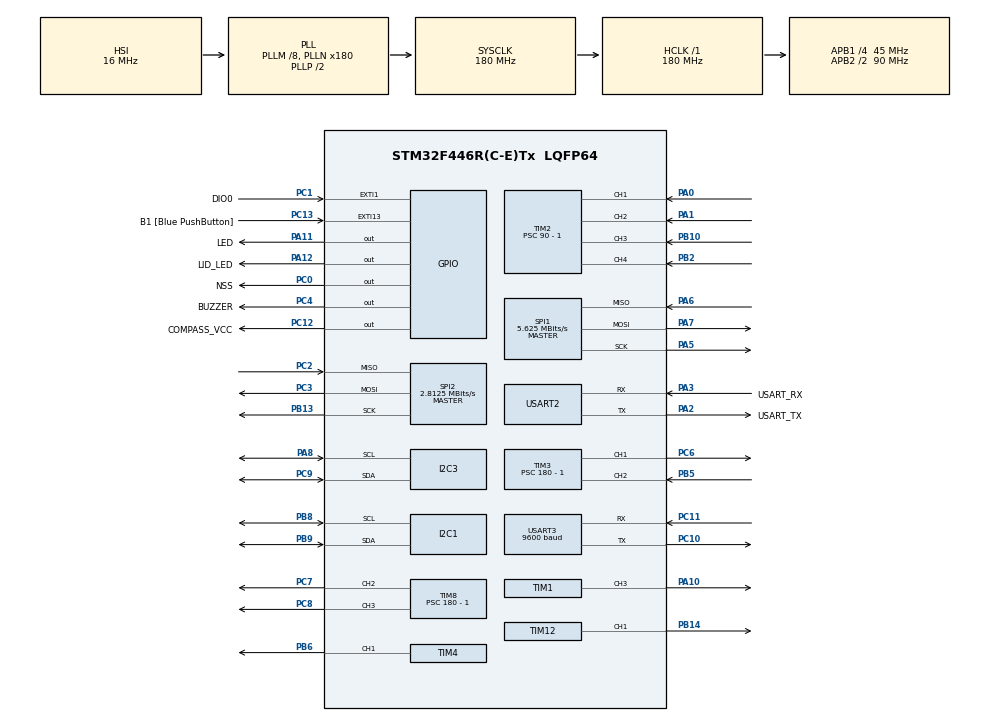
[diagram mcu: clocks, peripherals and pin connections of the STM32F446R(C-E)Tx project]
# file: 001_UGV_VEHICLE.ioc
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FREERTOS.Tasks01=defaultTask,24,128,StartDefaultTask,Default,NULL,Dynamic,NULL,NULL
FREERTOS.configUSE_NEWLIB_REENTRANT=1
IWDG.Prescaler=IWDG_PRESCALER_8
IWDG.Reload=2000
Mcu.Family=STM32F4
Mcu.Name=STM32F446R(C-E)Tx
Mcu.Package=LQFP64
NVIC.EXTI1_IRQn=true\:5\:0\:false\:false\:true\:true\:true\:true\:true
NVIC.PriorityGroup=NVIC_PRIORITYGROUP_4
NVIC.TIM2_IRQn=true\:5\:0\:false\:false\:true\:true\:true\:true\:true
NVIC.TIM6_DAC_IRQn=true\:15\:0\:false\:false\:true\:false\:false\:true\:true
NVIC.TimeBase=TIM6_DAC_IRQn
NVIC.TimeBaseIP=TIM6
NVIC.USART3_IRQn=true\:5\:0\:false\:false\:true\:true\:true\:true\:true
PA0-WKUP.Signal=S_TIM2_CH1_ETR
PA1.Signal=S_TIM2_CH2
PA10.Signal=S_TIM1_CH3
PA11.GPIO_Label=LED
PA11.Signal=GPIO_Output
PA12.GPIO_Label=LID_LED
PA12.Signal=GPIO_Output
PA13.GPIO_Label=TMS
PA13.Mode=Serial_Wire
PA13.Signal=SYS_JTMS-SWDIO
PA14.GPIO_Label=TCK
PA14.Mode=Serial_Wire
PA14.Signal=SYS_JTCK-SWCLK
PA2.GPIO_Label=USART_TX
PA2.Mode=Asynchronous
PA2.Signal=USART2_TX
PA3.GPIO_Label=USART_RX
PA3.Mode=Asynchronous
PA3.Signal=USART2_RX
PA5.Mode=Full_Duplex_Master
PA5.Signal=SPI1_SCK
PA6.Mode=Full_Duplex_Master
PA6.Signal=SPI1_MISO
PA7.Mode=Full_Duplex_Master
PA7.Signal=SPI1_MOSI
PA8.Mode=I2C
PA8.Signal=I2C3_SCL
PB10.Signal=S_TIM2_CH3
PB13.Mode=Full_Duplex_Master
PB13.Signal=SPI2_SCK
PB14.Signal=S_TIM12_CH1
PB2.Signal=S_TIM2_CH4
PB3.GPIO_Label=SWO
PB3.Signal=SYS_JTDO-SWO
PB5.Signal=S_TIM3_CH2
PB6.Signal=S_TIM4_CH1
PB8.Mode=I2C
PB8.Signal=I2C1_SCL
PB9.Mode=I2C
PB9.Signal=I2C1_SDA
PC0.GPIO_Label=NSS
PC0.PinState=GPIO_PIN_SET
PC0.Signal=GPIO_Output
PC1.GPIO_Label=DIO0
PC1.Signal=GPXTI1
PC10.Mode=Asynchronous
PC10.Signal=USART3_TX
PC11.Mode=Asynchronous
PC11.Signal=USART3_RX
PC12.GPIO_Label=COMPASS_VCC
PC12.Signal=GPIO_Output
PC13.GPIO_Label=B1 [Blue PushButton]
PC13.GPIO_ModeDefaultEXTI=GPIO_MODE_IT_FALLING
PC13.Signal=GPXTI13
PC2.Mode=Full_Duplex_Master
PC2.Signal=SPI2_MISO
PC3.Mode=Full_Duplex_Master
PC3.Signal=SPI2_MOSI
PC4.GPIO_Label=BUZZER
PC4.Signal=GPIO_Output
PC6.Signal=S_TIM3_CH1
PC7.Signal=S_TIM8_CH2
PC8.Signal=S_TIM8_CH3
PC9.Mode=I2C
PC9.Signal=I2C3_SDA
PH0-OSC_IN.Mode=HSE-External-Oscillator
PH0-OSC_IN.Signal=RCC_OSC_IN
PH1-OSC_OUT.Mode=HSE-External-Oscillator
PH1-OSC_OUT.Signal=RCC_OSC_OUT
ProjectManager.HeapSize=0x200
ProjectManager.StackSize=0x400
ProjectManager.TargetToolchain=STM32CubeIDE
RCC.48MHZClocksFreq_Value=84000000
RCC.AHBFreq_Value=180000000
RCC.APB1CLKDivider=RCC_HCLK_DIV4
RCC.APB1Freq_Value=45000000
RCC.APB1TimFreq_Value=90000000
RCC.APB2CLKDivider=RCC_HCLK_DIV2
RCC.APB2Freq_Value=90000000
RCC.APB2TimFreq_Value=180000000
RCC.CortexFreq_Value=180000000
RCC.FLatency-AdvancedSettings=FLASH_LATENCY_5
RCC.HCLKFreq_Value=180000000
RCC.HSE_VALUE=8000000
RCC.HSI_VALUE=16000000
RCC.PLLM=8
RCC.PLLN=180
RCC.SYSCLKFreq_VALUE=180000000
RCC.SYSCLKSource=RCC_SYSCLKSOURCE_PLLCLK
RCC.USBFreq_Value=180000000
RCC.VCOOutputFreq_Value=360000000
SH.S_TIM12_CH1.0=TIM12_CH1,PWM Generation1 CH1
SH.S_TIM1_CH3.0=TIM1_CH3,PWM Generation3 CH3
SH.S_TIM2_CH1_ETR.0=TIM2_CH1,Input_Capture1_from_TI1
SH.S_TIM2_CH2.0=TIM2_CH2,Input_Capture2_from_TI2
SH.S_TIM2_CH3.0=TIM2_CH3,Input_Capture3_from_TI3
SH.S_TIM2_CH4.0=TIM2_CH4,Input_Capture4_from_TI4
SH.S_TIM3_CH1.0=TIM3_CH1,PWM Generation1 CH1
SH.S_TIM3_CH2.0=TIM3_CH2,Input_Capture2_from_TI2
SH.S_TIM4_CH1.0=TIM4_CH1,PWM Generation1 CH1
SH.S_TIM8_CH2.0=TIM8_CH2,PWM Generation2 CH2
SH.S_TIM8_CH3.0=TIM8_CH3,PWM Generation3 CH3
SPI1.BaudRatePrescaler=SPI_BAUDRATEPRESCALER_16
SPI1.CalculateBaudRate=5.625 MBits/s
SPI1.Direction=SPI_DIRECTION_2LINES
SPI1.Mode=SPI_MODE_MASTER
SPI1.VirtualType=VM_MASTER
SPI2.BaudRatePrescaler=SPI_BAUDRATEPRESCALER_16
SPI2.CalculateBaudRate=2.8125 MBits/s
SPI2.Direction=SPI_DIRECTION_2LINES
SPI2.Mode=SPI_MODE_MASTER
SPI2.VirtualType=VM_MASTER
TIM1.Channel-PWM\ Generation3\ CH3=TIM_CHANNEL_3
TIM1.Period=100
TIM1.Prescaler=180  - 1
TIM12.Channel-PWM\ Generation1\ CH1=TIM_CHANNEL_1
TIM12.Period=1000-1
TIM12.Prescaler=1800-1
TIM2.Channel-Input_Capture1_from_TI1=TIM_CHANNEL_1
TIM2.Channel-Input_Capture2_from_TI2=TIM_CHANNEL_2
TIM2.Channel-Input_Capture3_from_TI3=TIM_CHANNEL_3
TIM2.Channel-Input_Capture4_from_TI4=TIM_CHANNEL_4
TIM2.ICPolarity_CH1=TIM_INPUTCHANNELPOLARITY_BOTHEDGE
TIM2.ICPolarity_CH2=TIM_INPUTCHANNELPOLARITY_BOTHEDGE
TIM2.ICPolarity_CH3=TIM_INPUTCHANNELPOLARITY_BOTHEDGE
TIM2.ICPolarity_CH4=TIM_INPUTCHANNELPOLARITY_BOTHEDGE
TIM2.Prescaler=90 - 1
TIM3.Channel-Input_Capture2_from_TI2=TIM_CHANNEL_2
TIM3.Channel-PWM\ Generation1\ CH1=TIM_CHANNEL_1
TIM3.Period=100
TIM3.Prescaler=180 - 1
TIM4.Channel-PWM\ Generation1\ CH1=TIM_CHANNEL_1
TIM4.Period=100
TIM4.Prescaler=180 - 1
TIM8.Channel-PWM\ Generation2\ CH2=TIM_CHANNEL_2
TIM8.Channel-PWM\ Generation3\ CH3=TIM_CHANNEL_3
TIM8.OCMode_PWM-PWM\ Generation3\ CH3=TIM_OCMODE_PWM1
TIM8.Period=100
TIM8.Prescaler=180 - 1
USART2.VirtualMode=VM_ASYNC
USART3.BaudRate=9600
USART3.VirtualMode=VM_ASYNC
VP_FREERTOS_VS_CMSIS_V2.Mode=CMSIS_V2
VP_IWDG_VS_IWDG.Mode=IWDG_Activate
VP_SYS_VS_tim6.Mode=TIM6
board=NUCLEO-F446RE

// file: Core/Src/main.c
/* USER CODE BEGIN Header */
/**
  ******************************************************************************
  * @file           : main.c
  * @brief          : Main program body
  ******************************************************************************
  * @attention
  *
  * Copyright (c) 2024 STMicroelectronics.
  * All rights reserved.
  *
  * This software is licensed under terms that can be found in the LICENSE file
  * in the root directory of this software component.
  * If no LICENSE file comes with this software, it is provided AS-IS.
  *
  ******************************************************************************
  */
/* USER CODE END Header */
#include "main.h"
#include "cmsis_os.h"
#include "i2c.h"
#include "iwdg.h"
#include "spi.h"
#include "tim.h"
#include "usart.h"
#include "gpio.h"

/* USER CODE BEGIN Includes */

#include "ugvMain.h"

/* USER CODE END Includes */

void SystemClock_Config(void);
void MX_FREERTOS_Init(void);

int main(void)
{

  /* MCU Configuration--------------------------------------------------------*/

  /* Reset of all peripherals, Initializes the Flash interface and the Systick. */
  HAL_Init();

  /* Configure the system clock */
  SystemClock_Config();

  /* Initialize all configured peripherals */
  MX_GPIO_Init();
  MX_USART2_UART_Init();
  MX_TIM2_Init();
  MX_SPI1_Init();
  MX_TIM12_Init();
  MX_I2C1_Init();
  MX_TIM3_Init();
  MX_TIM4_Init();
  MX_SPI2_Init();
  MX_USART3_UART_Init();
  MX_IWDG_Init();
  MX_TIM8_Init();
  MX_TIM1_Init();
  MX_I2C3_Init();

//  /* Init scheduler */
//  osKernelInitialize();
//
//  /* Call init function for freertos objects (in freertos.c) */
//  MX_FREERTOS_Init();
//
//  /* Start scheduler */
//  osKernelStart();
//
//  /* We should never get here as control is now taken by the scheduler */
//  /* Infinite loop */
//  /* USER CODE BEGIN WHILE */

  while (1)
  {
    /* USER CODE END WHILE */

    /* USER CODE BEGIN 3 */

	  ugvMain();
	  break;

  }
  /* USER CODE END 3 */
}

void SystemClock_Config(void)
{
  RCC_OscInitTypeDef RCC_OscInitStruct = {0};
  RCC_ClkInitTypeDef RCC_ClkInitStruct = {0};

  /** Configure the main internal regulator output voltage
  */
  __HAL_RCC_PWR_CLK_ENABLE();
  __HAL_PWR_VOLTAGESCALING_CONFIG(PWR_REGULATOR_VOLTAGE_SCALE1);

  /** Initializes the RCC Oscillators according to the specified parameters
  * in the RCC_OscInitTypeDef structure.
  */
  RCC_OscInitStruct.OscillatorType = RCC_OSCILLATORTYPE_HSI|RCC_OSCILLATORTYPE_LSI;
  RCC_OscInitStruct.HSIState = RCC_HSI_ON;
  RCC_OscInitStruct.HSICalibrationValue = RCC_HSICALIBRATION_DEFAULT;
  RCC_OscInitStruct.LSIState = RCC_LSI_ON;
  RCC_OscInitStruct.PLL.PLLState = RCC_PLL_ON;
  RCC_OscInitStruct.PLL.PLLSource = RCC_PLLSOURCE_HSI;
  RCC_OscInitStruct.PLL.PLLM = 8;
  RCC_OscInitStruct.PLL.PLLN = 180;
  RCC_OscInitStruct.PLL.PLLP = RCC_PLLP_DIV2;
  RCC_OscInitStruct.PLL.PLLQ = 2;
  RCC_OscInitStruct.PLL.PLLR = 2;
  if (HAL_RCC_OscConfig(&RCC_OscInitStruct) != HAL_OK)
  {
    Error_Handler();
  }

  /** Activate the Over-Drive mode
  */
  if (HAL_PWREx_EnableOverDrive() != HAL_OK)
  {
    Error_Handler();
  }

  /** Initializes the CPU, AHB and APB buses clocks
  */
  RCC_ClkInitStruct.ClockType = RCC_CLOCKTYPE_HCLK|RCC_CLOCKTYPE_SYSCLK
                              |RCC_CLOCKTYPE_PCLK1|RCC_CLOCKTYPE_PCLK2;
  RCC_ClkInitStruct.SYSCLKSource = RCC_SYSCLKSOURCE_PLLCLK;
  RCC_ClkInitStruct.AHBCLKDivider = RCC_SYSCLK_DIV1;
  RCC_ClkInitStruct.APB1CLKDivider = RCC_HCLK_DIV4;
  RCC_ClkInitStruct.APB2CLKDivider = RCC_HCLK_DIV2;

  if (HAL_RCC_ClockConfig(&RCC_ClkInitStruct, FLASH_LATENCY_5) != HAL_OK)
  {
    Error_Handler();
  }
}

void HAL_TIM_PeriodElapsedCallback(TIM_HandleTypeDef *htim)
{
  if (htim->Instance == TIM6) {
    HAL_IncTick();
  }
}

void Error_Handler(void)
{
  __disable_irq();
  while (1)
  {
  }
}
